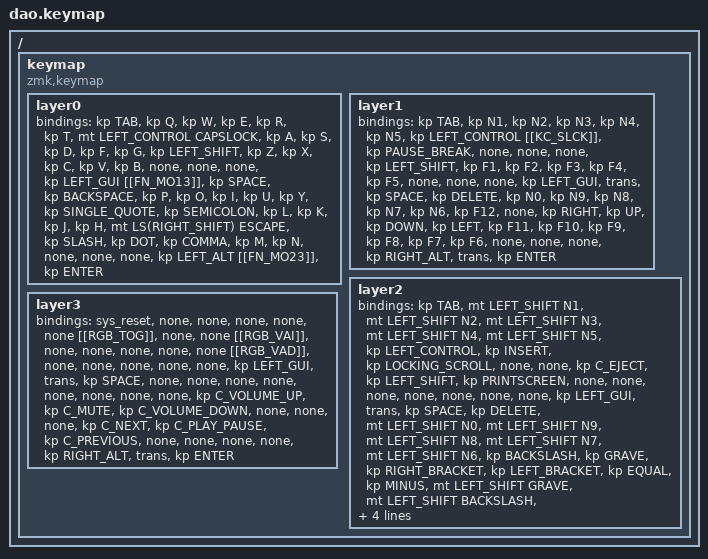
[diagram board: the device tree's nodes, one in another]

  /*
  * Copyright (c) 2020 The ZMK Contributors
  *
  * SPDX-License-Identifier: MIT
  */

  #include <behaviors.dtsi>
  #include <dt-bindings/zmk/keys.h>
  #include <dt-bindings/zmk/bt.h>
  #include <dt-bindings/zmk/ext_power.h>

  / {
    keymap {
      compatible = "zmk,keymap";
  layer0 {
          bindings = <
          &kp TAB &kp Q &kp W &kp E &kp R &kp T &mt LEFT_CONTROL CAPSLOCK &kp A &kp S &kp D &kp F &kp G &kp LEFT_SHIFT &kp Z &kp X &kp C &kp V &kp B &none &none &none &kp LEFT_GUI [[FN_MO13]] &kp SPACE &kp BACKSPACE &kp P &kp O &kp I &kp U &kp Y &kp SINGLE_QUOTE &kp SEMICOLON &kp L &kp K &kp J &kp H &mt LS(RIGHT_SHIFT) ESCAPE &kp SLASH &kp DOT &kp COMMA &kp M &kp N &none &none &none &kp LEFT_ALT [[FN_MO23]] &kp ENTER
          >;
        };layer1 {
          bindings = <
          &kp TAB &kp N1 &kp N2 &kp N3 &kp N4 &kp N5 &kp LEFT_CONTROL [[KC_SLCK]] &kp PAUSE_BREAK &none &none &none &kp LEFT_SHIFT &kp F1 &kp F2 &kp F3 &kp F4 &kp F5 &none &none &none &kp LEFT_GUI &trans &kp SPACE &kp DELETE &kp N0 &kp N9 &kp N8 &kp N7 &kp N6 &kp F12 &none &kp RIGHT &kp UP &kp DOWN &kp LEFT &kp F11 &kp F10 &kp F9 &kp F8 &kp F7 &kp F6 &none &none &none &kp RIGHT_ALT &trans &kp ENTER
          >;
        };layer2 {
          bindings = <
          &kp TAB &mt LEFT_SHIFT N1 &mt LEFT_SHIFT N2 &mt LEFT_SHIFT N3 &mt LEFT_SHIFT N4 &mt LEFT_SHIFT N5 &kp LEFT_CONTROL &kp INSERT &kp LOCKING_SCROLL &none &none &kp C_EJECT &kp LEFT_SHIFT &kp PRINTSCREEN &none &none &none &none &none &none &none &kp LEFT_GUI &trans &kp SPACE &kp DELETE &mt LEFT_SHIFT N0 &mt LEFT_SHIFT N9 &mt LEFT_SHIFT N8 &mt LEFT_SHIFT N7 &mt LEFT_SHIFT N6 &kp BACKSLASH &kp GRAVE &kp RIGHT_BRACKET &kp LEFT_BRACKET &kp EQUAL &kp MINUS &mt LEFT_SHIFT GRAVE &mt LEFT_SHIFT BACKSLASH &mt LEFT_SHIFT RIGHT_BRACKET &kp HOME &mt LEFT_SHIFT EQUAL &mt LEFT_SHIFT MINUS &none &none &none &kp RIGHT_ALT &trans &kp ENTER
          >;
        };layer3 {
          bindings = <
          &sys_reset &none &none &none &none &none [[RGB_TOG]] &none &none [[RGB_VAI]] &none &none &none &none &none [[RGB_VAD]] &none &none &none &none &none &kp LEFT_GUI &trans &kp SPACE &none &none &none &none &none &none &none &none &kp C_VOLUME_UP &kp C_MUTE &kp C_VOLUME_DOWN &none &none &none &kp C_NEXT &kp C_PLAY_PAUSE &kp C_PREVIOUS &none &none &none &none &kp RIGHT_ALT &trans &kp ENTER
          >;
        };
    };
  };
  
